VERSION ""

NS_ :

BS_:

BU_: SENSOR_SIM ECU_FADEC FLIGHT_CTRL GCS

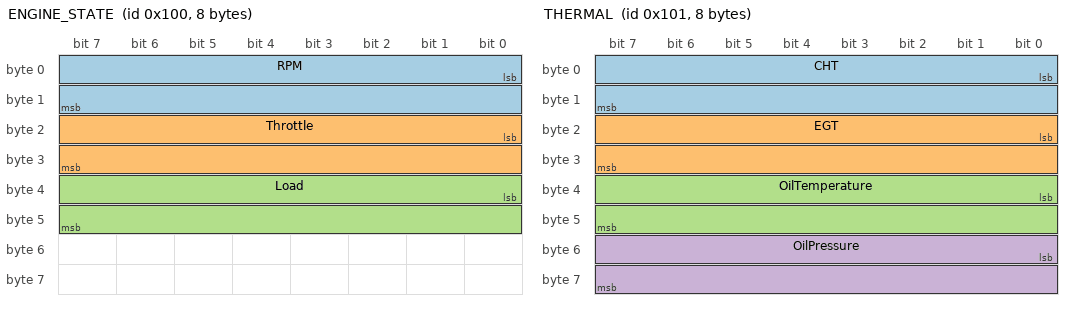
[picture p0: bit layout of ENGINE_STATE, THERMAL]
BO_ 256 ENGINE_STATE: 8 SENSOR_SIM
 SG_ RPM : 0|16@1+ (1,0) [0|10000] "rpm" ECU_FADEC
 SG_ Throttle : 16|16@1+ (0.01,0) [0|100] "%" ECU_FADEC
 SG_ Load : 32|16@1+ (0.01,0) [0|100] "%" ECU_FADEC

BO_ 257 THERMAL: 8 SENSOR_SIM
 SG_ CHT : 0|16@1+ (0.1,0) [-100|400] "degC" ECU_FADEC
 SG_ EGT : 16|16@1+ (0.1,0) [0|1000] "degC" ECU_FADEC
 SG_ OilTemperature : 32|16@1+ (0.1,0) [-100|300] "degC" ECU_FADEC
 SG_ OilPressure : 48|16@1+ (0.01,0) [0|20] "bar" ECU_FADEC

BO_ 258 AIR_FUEL: 8 SENSOR_SIM
 SG_ AirMassFlow : 0|16@1+ (0.0001,0) [0|6.5] "kg/s" ECU_FADEC
 SG_ FuelFlow : 16|16@1+ (0.0001,0) [0|6.5] "kg/s" ECU_FADEC

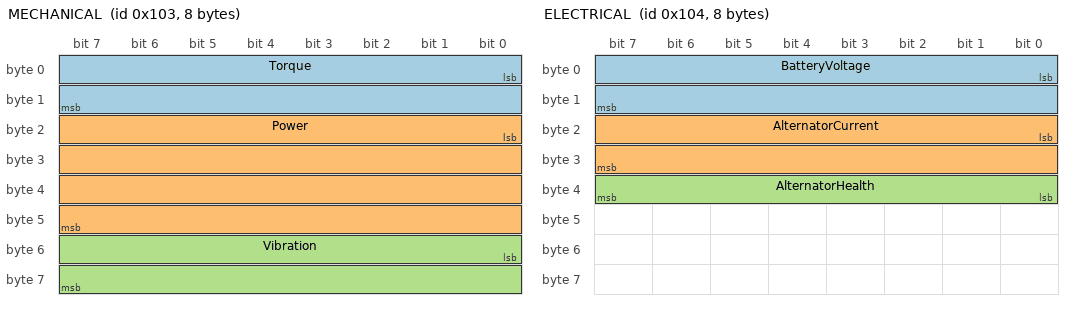
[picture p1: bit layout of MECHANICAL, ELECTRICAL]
BO_ 259 MECHANICAL: 8 SENSOR_SIM
 SG_ Torque : 0|16@1+ (0.01,0) [0|655.35] "Nm" ECU_FADEC
 SG_ Power : 16|32@1+ (1,0) [0|4294967295] "W" ECU_FADEC
 SG_ Vibration : 48|16@1+ (0.001,0) [0|65.535] "g" ECU_FADEC

BO_ 260 ELECTRICAL: 8 SENSOR_SIM
 SG_ BatteryVoltage : 0|16@1+ (0.01,0) [0|655.35] "V" ECU_FADEC
 SG_ AlternatorCurrent : 16|16@1+ (0.01,0) [0|655.35] "A" ECU_FADEC
 SG_ AlternatorHealth : 32|8@1+ (0.01,0) [0|2.55] "" ECU_FADEC

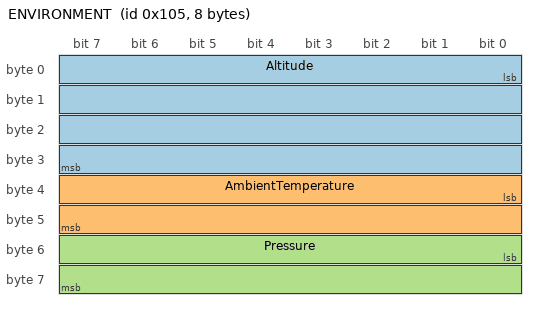
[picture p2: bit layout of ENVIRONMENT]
BO_ 261 ENVIRONMENT: 8 SENSOR_SIM
 SG_ Altitude : 0|32@1+ (0.1,0) [0|429496729.5] "m" ECU_FADEC
 SG_ AmbientTemperature : 32|16@1+ (0.1,0) [-100|300] "degC" ECU_FADEC
 SG_ Pressure : 48|16@1+ (0.01,0) [0|655.35] "kPa" ECU_FADEC

BO_ 262 INJECTION: 8 SENSOR_SIM
 SG_ InjectionTiming : 0|16@1+ (0.01,0) [-327.68|327.67] "deg" ECU_FADEC

BO_ 263 AIR_DENSITY: 8 SENSOR_SIM
 SG_ AirDensity : 0|16@1+ (0.0001,0) [0|6.5535] "kg/m3" ECU_FADEC
